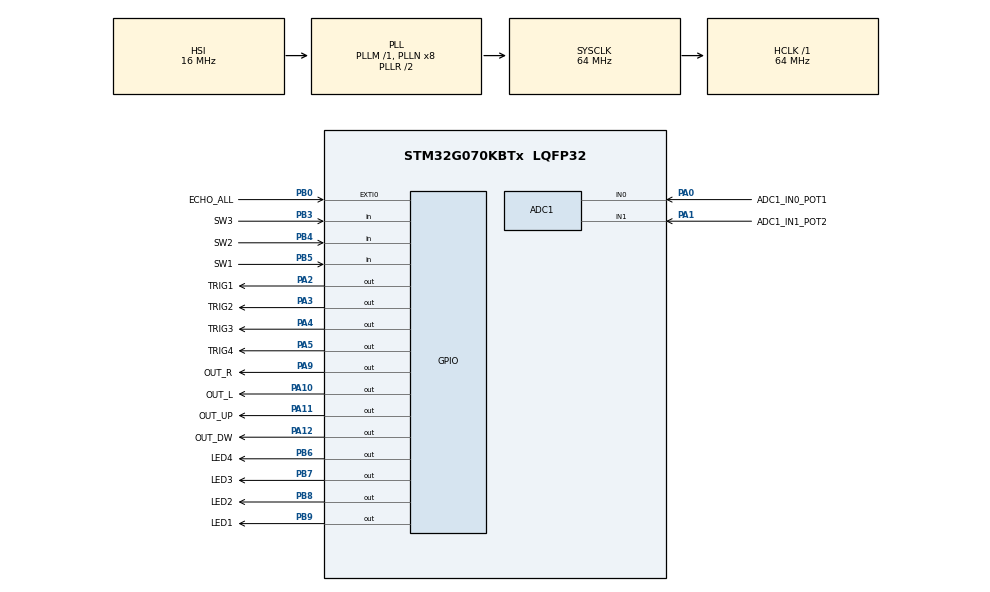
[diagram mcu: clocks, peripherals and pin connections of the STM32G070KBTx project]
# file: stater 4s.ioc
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ADC1.Channel-0\#ChannelRegularConversion=ADC_CHANNEL_0
ADC1.Channel-1\#ChannelRegularConversion=ADC_CHANNEL_1
ADC1.ContinuousConvMode=ENABLE
ADC1.EOCSelection=ADC_EOC_SEQ_CONV
ADC1.NbrOfConversion=2
ADC1.NbrOfConversionFlag=1
ADC1.Rank-0\#ChannelRegularConversion=1
ADC1.Rank-1\#ChannelRegularConversion=2
ADC1.SamplingTime-0\#ChannelRegularConversion=ADC_SAMPLINGTIME_COMMON_1
ADC1.SamplingTime-1\#ChannelRegularConversion=ADC_SAMPLINGTIME_COMMON_1
ADC1.SamplingTimeCommon1=ADC_SAMPLETIME_160CYCLES_5
ADC1.SamplingTimeCommon2=ADC_SAMPLETIME_160CYCLES_5
ADC1.SelectedChannel=ADC_CHANNEL_0|ADC_CHANNEL_1
ADC1.master=1
Mcu.Family=STM32G0
Mcu.Name=STM32G070KBTx
Mcu.Package=LQFP32
PA0.GPIO_Label=ADC1_IN0_POT1
PA0.Mode=IN0
PA0.Signal=ADC1_IN0
PA1.GPIO_Label=ADC1_IN1_POT2
PA1.Mode=IN1
PA1.Signal=ADC1_IN1
PA10.GPIO_Label=OUT_L
PA10.Signal=GPIO_Output
PA11\ [PA9].GPIO_Label=OUT_UP
PA11\ [PA9].Signal=GPIO_Output
PA12\ [PA10].GPIO_Label=OUT_DW
PA12\ [PA10].Signal=GPIO_Output
PA13.Mode=Serial_Wire
PA13.Signal=SYS_SWDIO
PA14-BOOT0.Mode=Serial_Wire
PA14-BOOT0.Signal=SYS_SWCLK
PA2.GPIO_Label=TRIG1
PA2.Signal=GPIO_Output
PA3.GPIO_Label=TRIG2
PA3.Signal=GPIO_Output
PA4.GPIO_Label=TRIG3
PA4.Signal=GPIO_Output
PA5.GPIO_Label=TRIG4
PA5.Signal=GPIO_Output
PA9.GPIO_Label=OUT_R
PA9.Signal=GPIO_Output
PB0.GPIO_Label=ECHO_ALL
PB0.Signal=GPXTI0
PB3.GPIO_Label=SW3
PB3.Signal=GPIO_Input
PB4.GPIO_Label=SW2
PB4.Signal=GPIO_Input
PB5.GPIO_Label=SW1
PB5.Signal=GPIO_Input
PB6.GPIO_Label=LED4
PB6.Signal=GPIO_Output
PB7.GPIO_Label=LED3
PB7.Signal=GPIO_Output
PB8.GPIO_Label=LED2
PB8.Signal=GPIO_Output
PB9.GPIO_Label=LED1
PB9.Signal=GPIO_Output
ProjectManager.HeapSize=0x200
ProjectManager.StackSize=0x400
ProjectManager.TargetToolchain=TrueSTUDIO
RCC.ADCFreq_Value=64000000
RCC.AHBFreq_Value=64000000
RCC.CortexFreq_Value=64000000
RCC.EXTERNAL_CLOCK_VALUE=48000
RCC.HCLKFreq_Value=64000000
RCC.HSE_VALUE=8000000
RCC.HSI_VALUE=16000000
RCC.LSE_VALUE=32768
RCC.SYSCLKFreq_VALUE=64000000
RCC.SYSCLKSource=RCC_SYSCLKSOURCE_PLLCLK
RCC.VCOOutputFreq_Value=128000000
TIM1.Channel-Input_Capture1_from_TRC=TIM_CHANNEL_1
VP_SYS_VS_DBSignals.Mode=DisableDeadBatterySignals
VP_TIM1_VS_ClockSourceINT.Mode=Internal
VP_TIM1_VS_ClockSourceITR.Mode=TriggerSource_ITR0
board=custom

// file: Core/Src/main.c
/* USER CODE BEGIN Header */
/**
  ******************************************************************************
  * @file           : main.c
  * @brief          : Main program body
  ******************************************************************************
  * @attention
  *
  * <h2><center>&copy; Copyright (c) 2021 STMicroelectronics.
  * All rights reserved.</center></h2>
  *
  * This software component is licensed by ST under BSD 3-Clause license,
  * the "License"; You may not use this file except in compliance with the
  * License. You may obtain a copy of the License at:
  *                        opensource.org/licenses/BSD-3-Clause
  *
  ******************************************************************************
  */
/* USER CODE END Header */
#include "main.h"

ADC_HandleTypeDef hadc1;
DMA_HandleTypeDef hdma_adc1;

TIM_HandleTypeDef htim1;

void SystemClock_Config(void);
static void MX_GPIO_Init(void);
static void MX_DMA_Init(void);
static void MX_ADC1_Init(void);
static void MX_TIM1_Init(void);
/* USER CODE BEGIN PFP */
extern void main_content(void);
extern void loop_content(void);

/* USER CODE END PFP */

int main(void)
{

  /* MCU Configuration--------------------------------------------------------*/

  /* Reset of all peripherals, Initializes the Flash interface and the Systick. */
  HAL_Init();

  /* Configure the system clock */
  SystemClock_Config();

  /* Initialize all configured peripherals */
  MX_GPIO_Init();
  MX_DMA_Init();
  MX_ADC1_Init();
  MX_TIM1_Init();
  /* USER CODE BEGIN 2 */
  main_content();
  /* USER CODE END 2 */

  /* Infinite loop */
  /* USER CODE BEGIN WHILE */
  while (1)
  {
	  loop_content();
    /* USER CODE END WHILE */

  }
}

void SystemClock_Config(void)
{
  RCC_OscInitTypeDef RCC_OscInitStruct = {0};
  RCC_ClkInitTypeDef RCC_ClkInitStruct = {0};
  RCC_PeriphCLKInitTypeDef PeriphClkInit = {0};

  /** Configure the main internal regulator output voltage
  */
  HAL_PWREx_ControlVoltageScaling(PWR_REGULATOR_VOLTAGE_SCALE1);
  /** Initializes the RCC Oscillators according to the specified parameters
  * in the RCC_OscInitTypeDef structure.
  */
  RCC_OscInitStruct.OscillatorType = RCC_OSCILLATORTYPE_HSI;
  RCC_OscInitStruct.HSIState = RCC_HSI_ON;
  RCC_OscInitStruct.HSIDiv = RCC_HSI_DIV1;
  RCC_OscInitStruct.HSICalibrationValue = RCC_HSICALIBRATION_DEFAULT;
  RCC_OscInitStruct.PLL.PLLState = RCC_PLL_ON;
  RCC_OscInitStruct.PLL.PLLSource = RCC_PLLSOURCE_HSI;
  RCC_OscInitStruct.PLL.PLLM = RCC_PLLM_DIV1;
  RCC_OscInitStruct.PLL.PLLN = 8;
  RCC_OscInitStruct.PLL.PLLP = RCC_PLLP_DIV2;
  RCC_OscInitStruct.PLL.PLLR = RCC_PLLR_DIV2;
  if (HAL_RCC_OscConfig(&RCC_OscInitStruct) != HAL_OK)
  {
    Error_Handler();
  }
  /** Initializes the CPU, AHB and APB buses clocks
  */
  RCC_ClkInitStruct.ClockType = RCC_CLOCKTYPE_HCLK|RCC_CLOCKTYPE_SYSCLK
                              |RCC_CLOCKTYPE_PCLK1;
  RCC_ClkInitStruct.SYSCLKSource = RCC_SYSCLKSOURCE_PLLCLK;
  RCC_ClkInitStruct.AHBCLKDivider = RCC_SYSCLK_DIV1;
  RCC_ClkInitStruct.APB1CLKDivider = RCC_HCLK_DIV1;

  if (HAL_RCC_ClockConfig(&RCC_ClkInitStruct, FLASH_LATENCY_2) != HAL_OK)
  {
    Error_Handler();
  }
  /** Initializes the peripherals clocks
  */
  PeriphClkInit.PeriphClockSelection = RCC_PERIPHCLK_ADC;
  PeriphClkInit.AdcClockSelection = RCC_ADCCLKSOURCE_SYSCLK;
  if (HAL_RCCEx_PeriphCLKConfig(&PeriphClkInit) != HAL_OK)
  {
    Error_Handler();
  }
}

static void MX_ADC1_Init(void)
{

  ADC_ChannelConfTypeDef sConfig = {0};

  /** Configure the global features of the ADC (Clock, Resolution, Data Alignment and number of conversion)
  */
  hadc1.Instance = ADC1;
  hadc1.Init.ClockPrescaler = ADC_CLOCK_SYNC_PCLK_DIV2;
  hadc1.Init.Resolution = ADC_RESOLUTION_12B;
  hadc1.Init.DataAlign = ADC_DATAALIGN_RIGHT;
  hadc1.Init.ScanConvMode = ADC_SCAN_ENABLE;
  hadc1.Init.EOCSelection = ADC_EOC_SEQ_CONV;
  hadc1.Init.LowPowerAutoWait = DISABLE;
  hadc1.Init.LowPowerAutoPowerOff = DISABLE;
  hadc1.Init.ContinuousConvMode = ENABLE;
  hadc1.Init.NbrOfConversion = 2;
  hadc1.Init.DiscontinuousConvMode = DISABLE;
  hadc1.Init.ExternalTrigConv = ADC_SOFTWARE_START;
  hadc1.Init.ExternalTrigConvEdge = ADC_EXTERNALTRIGCONVEDGE_NONE;
  hadc1.Init.DMAContinuousRequests = ENABLE;
  hadc1.Init.Overrun = ADC_OVR_DATA_PRESERVED;
  hadc1.Init.SamplingTimeCommon1 = ADC_SAMPLETIME_160CYCLES_5;
  hadc1.Init.SamplingTimeCommon2 = ADC_SAMPLETIME_160CYCLES_5;
  hadc1.Init.OversamplingMode = DISABLE;
  hadc1.Init.TriggerFrequencyMode = ADC_TRIGGER_FREQ_HIGH;
  if (HAL_ADC_Init(&hadc1) != HAL_OK)
  {
    Error_Handler();
  }
  /** Configure Regular Channel
  */
  sConfig.Channel = ADC_CHANNEL_0;
  sConfig.Rank = ADC_REGULAR_RANK_1;
  sConfig.SamplingTime = ADC_SAMPLINGTIME_COMMON_1;
  if (HAL_ADC_ConfigChannel(&hadc1, &sConfig) != HAL_OK)
  {
    Error_Handler();
  }
  /** Configure Regular Channel
  */
  sConfig.Channel = ADC_CHANNEL_1;
  sConfig.Rank = ADC_REGULAR_RANK_2;
  if (HAL_ADC_ConfigChannel(&hadc1, &sConfig) != HAL_OK)
  {
    Error_Handler();
  }

}

static void MX_TIM1_Init(void)
{

  TIM_ClockConfigTypeDef sClockSourceConfig = {0};
  TIM_SlaveConfigTypeDef sSlaveConfig = {0};
  TIM_MasterConfigTypeDef sMasterConfig = {0};
  TIM_BreakDeadTimeConfigTypeDef sBreakDeadTimeConfig = {0};

  htim1.Instance = TIM1;
  htim1.Init.Prescaler = 50;
  htim1.Init.CounterMode = TIM_COUNTERMODE_UP;
  htim1.Init.Period = 65535;
  htim1.Init.ClockDivision = TIM_CLOCKDIVISION_DIV1;
  htim1.Init.RepetitionCounter = 0;
  htim1.Init.AutoReloadPreload = TIM_AUTORELOAD_PRELOAD_DISABLE;
  if (HAL_TIM_Base_Init(&htim1) != HAL_OK)
  {
    Error_Handler();
  }
  sClockSourceConfig.ClockSource = TIM_CLOCKSOURCE_INTERNAL;
  if (HAL_TIM_ConfigClockSource(&htim1, &sClockSourceConfig) != HAL_OK)
  {
    Error_Handler();
  }
  sSlaveConfig.SlaveMode = TIM_SLAVEMODE_DISABLE;
  sSlaveConfig.InputTrigger = TIM_TS_ITR0;
  if (HAL_TIM_SlaveConfigSynchro(&htim1, &sSlaveConfig) != HAL_OK)
  {
    Error_Handler();
  }
  sMasterConfig.MasterOutputTrigger = TIM_TRGO_RESET;
  sMasterConfig.MasterOutputTrigger2 = TIM_TRGO2_RESET;
  sMasterConfig.MasterSlaveMode = TIM_MASTERSLAVEMODE_DISABLE;
  if (HAL_TIMEx_MasterConfigSynchronization(&htim1, &sMasterConfig) != HAL_OK)
  {
    Error_Handler();
  }
  sBreakDeadTimeConfig.BreakAFMode = TIM_BREAK_AFMODE_INPUT;
  sBreakDeadTimeConfig.Break2AFMode = TIM_BREAK_AFMODE_INPUT;
  if (HAL_TIMEx_ConfigBreakDeadTime(&htim1, &sBreakDeadTimeConfig) != HAL_OK)
  {
    Error_Handler();
  }

}

static void MX_DMA_Init(void)
{

  /* DMA controller clock enable */
  __HAL_RCC_DMA1_CLK_ENABLE();

  /* DMA interrupt init */
  /* DMA1_Channel1_IRQn interrupt configuration */
  HAL_NVIC_SetPriority(DMA1_Channel1_IRQn, 0, 0);
  HAL_NVIC_EnableIRQ(DMA1_Channel1_IRQn);

}

static void MX_GPIO_Init(void)
{
  GPIO_InitTypeDef GPIO_InitStruct = {0};

  /* GPIO Ports Clock Enable */
  __HAL_RCC_GPIOB_CLK_ENABLE();
  __HAL_RCC_GPIOA_CLK_ENABLE();

  /*Configure GPIO pin Output Level */
  HAL_GPIO_WritePin(GPIOB, LED1_Pin|LED4_Pin|LED3_Pin|LED2_Pin, GPIO_PIN_RESET);

  /*Configure GPIO pin Output Level */
  HAL_GPIO_WritePin(GPIOA, TRIG1_Pin|TRIG2_Pin|TRIG3_Pin|TRIG4_Pin
                          |OUT_R_Pin|OUT_L_Pin|OUT_UP_Pin|OUT_DW_Pin, GPIO_PIN_RESET);

  /*Configure GPIO pins : LED1_Pin LED4_Pin LED3_Pin LED2_Pin */
  GPIO_InitStruct.Pin = LED1_Pin|LED4_Pin|LED3_Pin|LED2_Pin;
  GPIO_InitStruct.Mode = GPIO_MODE_OUTPUT_PP;
  GPIO_InitStruct.Pull = GPIO_NOPULL;
  GPIO_InitStruct.Speed = GPIO_SPEED_FREQ_LOW;
  HAL_GPIO_Init(GPIOB, &GPIO_InitStruct);

  /*Configure GPIO pins : TRIG1_Pin TRIG2_Pin TRIG3_Pin TRIG4_Pin
                           OUT_R_Pin OUT_L_Pin OUT_UP_Pin OUT_DW_Pin */
  GPIO_InitStruct.Pin = TRIG1_Pin|TRIG2_Pin|TRIG3_Pin|TRIG4_Pin
                          |OUT_R_Pin|OUT_L_Pin|OUT_UP_Pin|OUT_DW_Pin;
  GPIO_InitStruct.Mode = GPIO_MODE_OUTPUT_PP;
  GPIO_InitStruct.Pull = GPIO_NOPULL;
  GPIO_InitStruct.Speed = GPIO_SPEED_FREQ_LOW;
  HAL_GPIO_Init(GPIOA, &GPIO_InitStruct);

  /*Configure GPIO pin : ECHO_ALL_Pin */
  GPIO_InitStruct.Pin = ECHO_ALL_Pin;
  GPIO_InitStruct.Mode = GPIO_MODE_IT_RISING_FALLING;
  GPIO_InitStruct.Pull = GPIO_NOPULL;
  HAL_GPIO_Init(ECHO_ALL_GPIO_Port, &GPIO_InitStruct);

  /*Configure GPIO pins : SW3_Pin SW2_Pin SW1_Pin */
  GPIO_InitStruct.Pin = SW3_Pin|SW2_Pin|SW1_Pin;
  GPIO_InitStruct.Mode = GPIO_MODE_INPUT;
  GPIO_InitStruct.Pull = GPIO_NOPULL;
  HAL_GPIO_Init(GPIOB, &GPIO_InitStruct);

  /* EXTI interrupt init*/
  HAL_NVIC_SetPriority(EXTI0_1_IRQn, 0, 0);
  HAL_NVIC_EnableIRQ(EXTI0_1_IRQn);

}

void Error_Handler(void)
{
}

/************************ (C) COPYRIGHT STMicroelectronics *****END OF FILE****/
